# STM32U5A5 register map
File version: 0.2
CPU: CM33 r0p1, little endian, MPU, FPU, 4 interrupt priority bits
Registers are 32-bit, read-write, reset 0x0 unless marked. A register's access mark holds for its fields unless they carry their own. Offsets are from the block's base; [hi:lo] are bit positions; 'fields as' and 'values as' point back to an identical list.

## OCTOSPIM — OCTOSPI I/O manager
Base 0x420C4000
Same registers: SEC_OCTOSPIM 0x520C4000
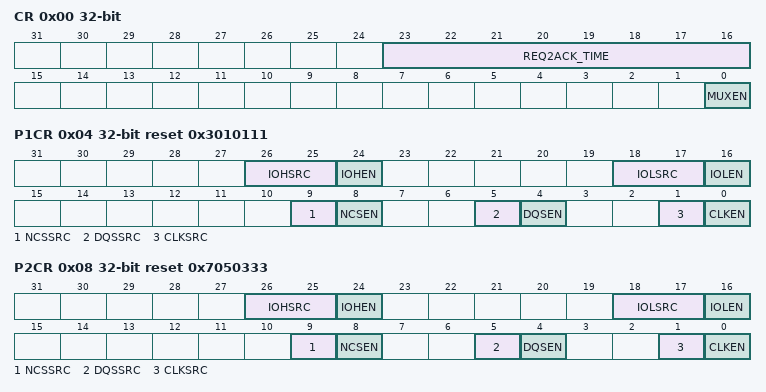
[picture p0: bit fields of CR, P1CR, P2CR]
0x00 CR — control register
  [23:16] REQ2ACK_TIME — REQ to ACK time
  [0] MUXEN — Multiplexed mode enable
0x04 P1CR reset 0x3010111 — OCTOSPI I/O manager Port 1 configuration register
  [26:25] IOHSRC — IOHSR
  [24] IOHEN
  [18:17] IOLSRC
  [16] IOLEN
  [9] NCSSRC
  [8] NCSEN
  [5] DQSSRC
  [4] DQSEN
  [1] CLKSRC
  [0] CLKEN
0x08 P2CR reset 0x7050333 — OCTOSPI I/O manager Port 2 configuration register
  fields as P1CR

## OPAMP — Operational amplifiers
Base 0x46005000
Same registers: SEC_OPAMP 0x56005000
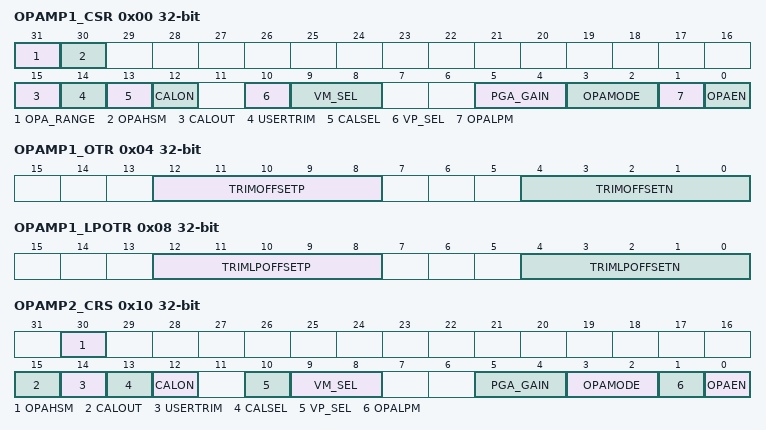
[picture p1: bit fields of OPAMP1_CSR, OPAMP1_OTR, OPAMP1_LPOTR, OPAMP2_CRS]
0x00 OPAMP1_CSR access per field — OPAMP1 control/status register
  [31] OPA_RANGE rw — OPAMP range setting This bit must be set before enabling the OPAMP and this bit affects all OPAMP instances.
  [30] OPAHSM rw — OPAMP high-speed mode This bit is effective for both normal and low-power modes.
  [15] CALOUT ro — OPAMP calibration output During the calibration mode, the offset is trimmed when this signal toggles.
  [14] USERTRIM rw — ‘factory’ or ‘user’ offset trimmed values selection This bit is active for normal and low-power modes.
  [13] CALSEL rw — Calibration selection
  [12] CALON rw — Calibration mode enable
  [10] VP_SEL rw — Non-inverted input selection
  [9:8] VM_SEL rw — Inverting input selection These bits are used only when OPAMODE = 00, 01 or 10. 1x: inverting input not externally connected
  [5:4] PGA_GAIN rw — OPAMP programmable amplifier gain value
  [3:2] OPAMODE rw — OPAMP PGA mode 00 and 01: internal PGA disabled
  [1] OPALPM rw — OPAMP low-power mode The OPAMP must be disabled to change this configuration.
  [0] OPAEN rw — OPAMP enable
0x04 OPAMP1_OTR (reset mask 0xFFFF0000) — OPAMP1 offset trimming register in normal mode
  [12:8] TRIMOFFSETP — Trim for PMOS differential pairs
  [4:0] TRIMOFFSETN — Trim for NMOS differential pairs
0x08 OPAMP1_LPOTR (reset mask 0xFFFF0000) — OPAMP1 offset trimming register in low-power mode
  [12:8] TRIMLPOFFSETP — Low-power mode trim for PMOS differential pairs
  [4:0] TRIMLPOFFSETN — Low-power mode trim for NMOS differential pairs
0x10 OPAMP2_CRS access per field — OPAMP2 control/status register
  [30] OPAHSM rw — OPAMP high-speed mode This bit is effective for both normal and high-speed modes.
  [15] CALOUT ro — OPAMP calibration output During calibration mode, the offset is trimmed when this signal toggles.
  [14] USERTRIM rw — ‘factory’ or ‘user’ offset trimmed values selection This bit is active for normal and low-power modes.
  [13] CALSEL rw — Calibration selection
  [12] CALON rw — Calibration mode enable
  [10] VP_SEL rw — Non inverted input selection
  [9:8] VM_SEL rw — Inverting input selection These bits are used only when OPAMODE = 00, 01 or 10. in PGA mode for filtering) 1x: inverting input not externally connected
  [5:4] PGA_GAIN rw — OPAMP programmable amplifier gain value
  [3:2] OPAMODE rw — OPAMP PGA mode 00 and 01: internal PGA disabled
  [1] OPALPM rw — OPAMP low-power mode The OPAMP must be disabled to change this configuration.
  [0] OPAEN rw — OPAMP enable
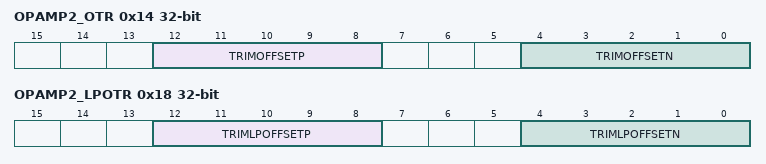
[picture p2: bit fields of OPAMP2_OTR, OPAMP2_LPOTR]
0x14 OPAMP2_OTR (reset mask 0xFFFF0000) — OPAMP2 offset trimming register in normal mode
  fields as OPAMP1_OTR
0x18 OPAMP2_LPOTR (reset mask 0xFFFF0000) — OPAMP2 offset trimming register in low-power mode
  fields as OPAMP1_LPOTR

## PKA — Private key accelerator
Base 0x420C2000
Same registers: SEC_PKA 0x520C2000
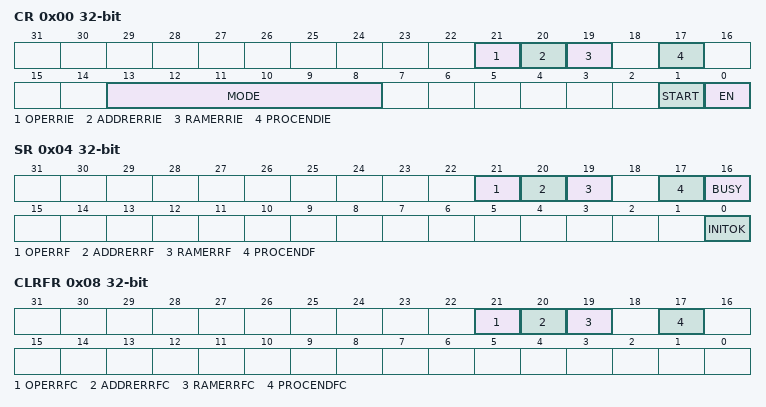
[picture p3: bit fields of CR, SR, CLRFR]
0x00 CR — Control register
  [21] OPERRIE — Operation error interrupt enable
  [20] ADDRERRIE — Address error interrupt enable
  [19] RAMERRIE — RAM error interrupt enable
  [17] PROCENDIE — End of operation interrupt enable
  [13:8] MODE — PKA Operation Mode
  [1] START — Start the operation
  [0] EN — Peripheral Enable
0x04 SR ro — PKA status register
  [21] OPERRF
  [20] ADDRERRF
  [19] RAMERRF
  [17] PROCENDF — PKA End of Operation flag
  [16] BUSY — PKA operation is in progress
  [0] INITOK
0x08 CLRFR wo — PKA clear flag register
  [21] OPERRFC
  [20] ADDRERRFC
  [19] RAMERRFC
  [17] PROCENDFC — Clear PKA End of Operation flag
